# ARMv8M-Baseline register map
Registers are read-only, no defined reset value unless marked. A register's access mark holds for its fields unless they carry their own. Offsets are from the block's base; [hi:lo] are bit positions; {n}, {i} and the like mark numbered series.

## FPB — Flash Patch and Breakpoint
Base 0xE0002000
0x00 FP_CTRL rw — Flash Patch Control Register provides FPB implementation information, and the global enable for the FPB unit
  [31:28] REV — Revision. Flash Patch and Breakpoint Unit architecture revision
    1=Flash Patch Breakpoint version 2 implemented
  [11:8] NUM_LIT — Number of literal comparators. Indicates the number of implemented literal address comparators
  [1] KEY — FP_CTRL write-enable key
    0=Concurrent write to FP_CTRL ignored; 1=Concurrent write to FP_CTRL permitted
  [0] NUM_CODE — Number of implemented code comparators
  [0] ENABLE — Flash Patch global enable. Enables the FPB
    0=All FPB functionality disabled; 1=FPB enabled
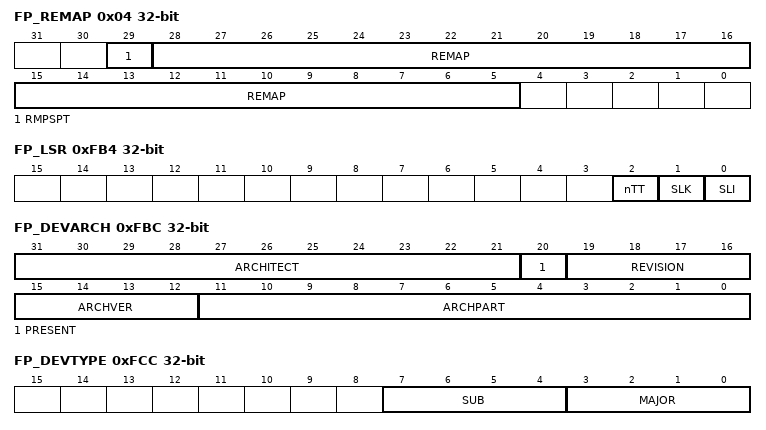
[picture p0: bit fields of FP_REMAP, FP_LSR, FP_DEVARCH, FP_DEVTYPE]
0x04 FP_REMAP — Flash Patch Remap Register indicates whether the implementation supports Flash Patch remap and, if it does, holds the target address for remap
  [29] RMPSPT — Remap supported. Indicates whether the FPB unit supports the Flash Patch remap function
    0=Flash Patch remap function is not implemented; 1=Flash Patch remap function is implemented
  [28:5] REMAP — Remap address. Holds the bits[28:5] of the Flash Patch remap address
{0x8+4i} FP_COMP[{i}] (i=0..140) rw — Flash Patch Comparator Register holds an address for comparison with addresses in the Code memory region
  [31] FE — Flash Patch enable. Specifies if Flash Patch enabled
    0=Flash Patch disabled; 1=Flash Patch enabled
  [28:2] FPADDR — Flash Patch address. Specifies bits[28:2] of the Flash Patch address
  [31:1] BPADDR — Breakpoint address. Specifies bits[31:1] of the breakpoint instruction address
  [0] BE — Breakpoint enable. Selects between Flash Patch and breakpoint functionality
    0=Breakpoint disabled, Flash Patch mode selected; 1=Breakpoint enabled, Flash Patch mode de-selected
0xFB0 FP_LAR wo — FPB Software Lock Access Register provides CoreSight Software Lock control for the FPB, see the CoreSight Architecture Specification for details
  [31:0] KEY — Lock Access control
0xFB4 FP_LSR — FPB Software Lock Status Register provides CoreSight Software Lock status information for the FPB, see the CoreSight Architecture Specification for details
  [2] nTT — Not thirty-two bit. See the CoreSight Architecture Specification
  [1] SLK — Software Lock status. See the CoreSight Architecture Specification
    0=Lock clear. Software writes are permitted to this component's registers; 1=Lock set
  [0] SLI — Software Lock implemented. See the CoreSight Architecture Specification
    0=Software Lock not implemented or debugger access; 1=Software Lock is implemented and software access
0xFBC FP_DEVARCH — FPB Device Architecture Register provides CoreSight discovery information for the FPB
  [31:21] ARCHITECT — Architect. Defines the architect of the component
    0x23B=JEP106 continuation code 0x4, ID code 0x3B. ARM Limited
  [20] PRESENT — DEVARCH Present. Defines that the DEVARCH register is present
    1=DEVARCH information present
  [19:16] REVISION — Revision. Defines the architecture revision of the component
    0=FPB architecture v2.0
  [15:12] ARCHVER — Architecture Version. Defines the architecture version of the component
    1=FPB architecture v2; 0=11ARCHPART12 15ARCHVER16 19REVISION20 21 31ARCHITECTPRESENTD1 Register Specification D1
  [11:0] ARCHPART — Architecture Part. Defines the architecture of the component
    0xA03=FPB architecture
0xFCC FP_DEVTYPE — FPB Device Type Register provides CoreSight discovery information for the FPB
  [7:4] SUB — Subtype. Component subtype
    0=Other
  [3:0] MAJOR — Major type. Component major type
    0=Miscellaneous
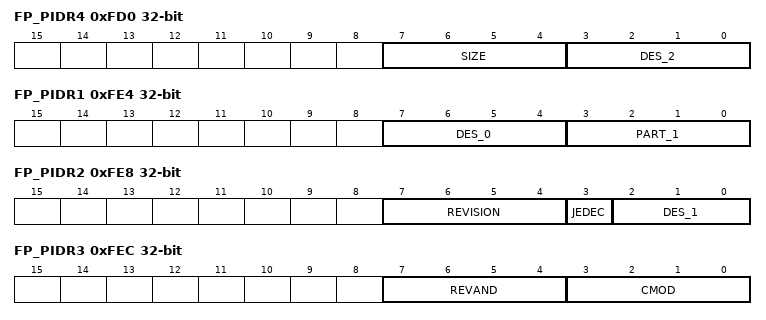
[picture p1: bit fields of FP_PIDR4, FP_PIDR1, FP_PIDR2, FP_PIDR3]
0xFD0 FP_PIDR4 — FP Peripheral Identification Register 4 provides CoreSight discovery information for the FP
  [7:4] SIZE — 4KB count. See the CoreSight Architecture Specification
  [3:0] DES_2 — JEP106 continuation code. See the CoreSight Architecture Specification
{0xFC0+4i} FP_PIDR{i} (i=5..7) — FP Peripheral Identification Register {i} provides CoreSight discovery information for the FP
0xFE0 FP_PIDR0 — FP Peripheral Identification Register 0 provides CoreSight discovery information for the FP
  [7:0] PART_0 — Part number bits [7:0]. See the CoreSight Architecture Specification
0xFE4 FP_PIDR1 — FP Peripheral Identification Register 1 provides CoreSight discovery information for the FP
  [7:4] DES_0 — JEP106 identification code bits [3:0]. See the CoreSight Architecture Specification
  [3:0] PART_1 — Part number bits [11:8]. See the CoreSight Architecture Specification
0xFE8 FP_PIDR2 — FP Peripheral Identification Register 2 provides CoreSight discovery information for the FP
  [7:4] REVISION — Component revision. See the CoreSight Architecture Specification
  [3] JEDEC — JEDEC assignee value is used. See the CoreSight Architecture Specification
  [2:0] DES_1 — JEP106 identification code bits [6:4]. See the CoreSight Architecture Specification
0xFEC FP_PIDR3 — FP Peripheral Identification Register 3 provides CoreSight discovery information for the FP
  [7:4] REVAND — RevAnd. See the CoreSight Architecture Specification
  [3:0] CMOD — Customer Modified. See the CoreSight Architecture Specification
0xFF0 FP_CIDR0 — FP Component Identification Register 0 provides CoreSight discovery information for the FP
  [7:0] PRMBL_0 — CoreSight component identification preamble
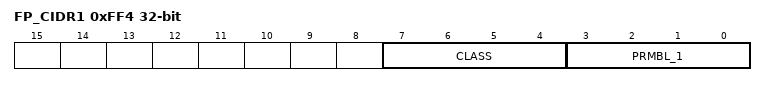
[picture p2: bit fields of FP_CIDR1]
0xFF4 FP_CIDR1 — FP Component Identification Register 1 provides CoreSight discovery information for the FP
  [7:4] CLASS — CoreSight component class. See the CoreSight Architecture Specification
  [3:0] PRMBL_1 — CoreSight component identification preamble
0xFF8 FP_CIDR2 — FP Component Identification Register 2 provides CoreSight discovery information for the FP
  [7:0] PRMBL_2 — CoreSight component identification preamble
0xFFC FP_CIDR3 — FP Component Identification Register 3 provides CoreSight discovery information for the FP
  [7:0] PRMBL_3 — CoreSight component identification preamble
